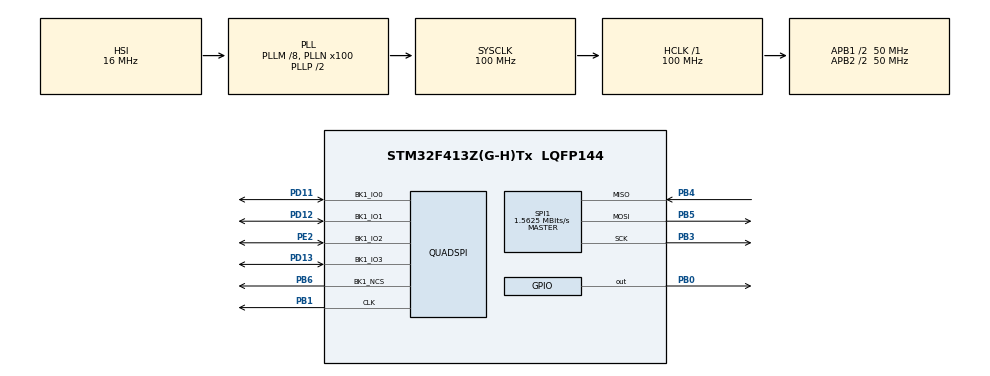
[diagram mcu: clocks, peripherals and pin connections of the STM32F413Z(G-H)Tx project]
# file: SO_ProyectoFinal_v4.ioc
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Mcu.Family=STM32F4
Mcu.Name=STM32F413Z(G-H)Tx
Mcu.Package=LQFP144
NVIC.PriorityGroup=NVIC_PRIORITYGROUP_4
PB0.GPIO_Speed=GPIO_SPEED_FREQ_VERY_HIGH
PB0.PinState=GPIO_PIN_SET
PB0.Signal=GPIO_Output
PB1.Mode=Single Bank 1
PB1.Signal=QUADSPI_CLK
PB3.Mode=Full_Duplex_Master
PB3.Signal=SPI1_SCK
PB4.Mode=Full_Duplex_Master
PB4.Signal=SPI1_MISO
PB5.Mode=Full_Duplex_Master
PB5.Signal=SPI1_MOSI
PB6.Mode=Single Bank 1
PB6.Signal=QUADSPI_BK1_NCS
PD11.Mode=Single Bank 1
PD11.Signal=QUADSPI_BK1_IO0
PD12.Mode=Single Bank 1
PD12.Signal=QUADSPI_BK1_IO1
PD13.Mode=Single Bank 1
PD13.Signal=QUADSPI_BK1_IO3
PE2.Mode=Single Bank 1
PE2.Signal=QUADSPI_BK1_IO2
ProjectManager.HeapSize=0x200
ProjectManager.StackSize=0x400
ProjectManager.TargetToolchain=STM32CubeIDE
QUADSPI.ClockPrescaler=1
QUADSPI.FifoThreshold=4
QUADSPI.FlashSize=21
QUADSPI.SampleShifting=QSPI_SAMPLE_SHIFTING_HALFCYCLE
RCC.AHBFreq_Value=100000000
RCC.APB1CLKDivider=RCC_HCLK_DIV2
RCC.APB1Freq_Value=50000000
RCC.APB1TimFreq_Value=100000000
RCC.APB2CLKDivider=RCC_HCLK_DIV2
RCC.APB2Freq_Value=50000000
RCC.APB2TimFreq_Value=100000000
RCC.CortexFreq_Value=100000000
RCC.HCLKFreq_Value=100000000
RCC.HSE_VALUE=8000000
RCC.PLLM=8
RCC.PLLN=100
RCC.SYSCLKFreq_VALUE=100000000
RCC.SYSCLKSource=RCC_SYSCLKSOURCE_PLLCLK
RCC.USBFreq_Value=100000000
RCC.VCOOutputFreq_Value=200000000
SPI1.BaudRatePrescaler=SPI_BAUDRATEPRESCALER_32
SPI1.CalculateBaudRate=1.5625 MBits/s
SPI1.Direction=SPI_DIRECTION_2LINES
SPI1.Mode=SPI_MODE_MASTER
SPI1.VirtualType=VM_MASTER
board=custom

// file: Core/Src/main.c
/* USER CODE BEGIN Header */
/**
  ******************************************************************************
  * @file           : main.c
  * @brief          : Main program body
  ******************************************************************************
  * @attention
  *
  * Copyright (c) 2023 STMicroelectronics.
  * All rights reserved.
  *
  * This software is licensed under terms that can be found in the LICENSE file
  * in the root directory of this software component.
  * If no LICENSE file comes with this software, it is provided AS-IS.
  *
  ******************************************************************************
  */
/* USER CODE END Header */
#include "main.h"
#include "quadspi.h"
#include "spi.h"
#include "gpio.h"

void SystemClock_Config(void);

/* USER CODE BEGIN 0 */

uint8_t writebuf[] = "Hello world from QSPI";
//uint8_t writebuf[] = "12345 54321";
uint8_t Readbuf[100];

/* USER CODE END 0 */

int main(void)
{

  /* MCU Configuration--------------------------------------------------------*/

  /* Reset of all peripherals, Initializes the Flash interface and the Systick. */
  HAL_Init();

  /* Configure the system clock */
  SystemClock_Config();

  /* Initialize all configured peripherals */
  MX_GPIO_Init();
  MX_SPI1_Init();
  MX_QUADSPI_Init();
  /* USER CODE BEGIN 2 */

  if (CSP_QUADSPI_Init() != HAL_OK) Error_Handler();

  if (CSP_QSPI_Erase_Chip() != HAL_OK) Error_Handler();

  if (CSP_QSPI_WriteMemory(writebuf, 0, sizeof(writebuf)) != HAL_OK) Error_Handler();

  if (CSP_QSPI_Read(Readbuf, 0, 100) != HAL_OK) Error_Handler();

  /* USER CODE END 2 */

  /* Infinite loop */
  while (1)
  {

  }
}

void SystemClock_Config(void)
{
  RCC_OscInitTypeDef RCC_OscInitStruct = {0};
  RCC_ClkInitTypeDef RCC_ClkInitStruct = {0};

  /** Configure the main internal regulator output voltage
  */
  __HAL_RCC_PWR_CLK_ENABLE();
  __HAL_PWR_VOLTAGESCALING_CONFIG(PWR_REGULATOR_VOLTAGE_SCALE1);

  /** Initializes the RCC Oscillators according to the specified parameters
  * in the RCC_OscInitTypeDef structure.
  */
  RCC_OscInitStruct.OscillatorType = RCC_OSCILLATORTYPE_HSI;
  RCC_OscInitStruct.HSIState = RCC_HSI_ON;
  RCC_OscInitStruct.HSICalibrationValue = RCC_HSICALIBRATION_DEFAULT;
  RCC_OscInitStruct.PLL.PLLState = RCC_PLL_ON;
  RCC_OscInitStruct.PLL.PLLSource = RCC_PLLSOURCE_HSI;
  RCC_OscInitStruct.PLL.PLLM = 8;
  RCC_OscInitStruct.PLL.PLLN = 100;
  RCC_OscInitStruct.PLL.PLLP = RCC_PLLP_DIV2;
  RCC_OscInitStruct.PLL.PLLQ = 2;
  RCC_OscInitStruct.PLL.PLLR = 2;
  if (HAL_RCC_OscConfig(&RCC_OscInitStruct) != HAL_OK)
  {
    Error_Handler();
  }

  /** Initializes the CPU, AHB and APB buses clocks
  */
  RCC_ClkInitStruct.ClockType = RCC_CLOCKTYPE_HCLK|RCC_CLOCKTYPE_SYSCLK
                              |RCC_CLOCKTYPE_PCLK1|RCC_CLOCKTYPE_PCLK2;
  RCC_ClkInitStruct.SYSCLKSource = RCC_SYSCLKSOURCE_PLLCLK;
  RCC_ClkInitStruct.AHBCLKDivider = RCC_SYSCLK_DIV1;
  RCC_ClkInitStruct.APB1CLKDivider = RCC_HCLK_DIV2;
  RCC_ClkInitStruct.APB2CLKDivider = RCC_HCLK_DIV2;

  if (HAL_RCC_ClockConfig(&RCC_ClkInitStruct, FLASH_LATENCY_3) != HAL_OK)
  {
    Error_Handler();
  }
}

void Error_Handler(void)
{
  __disable_irq();
  while (1)
  {
  }
}
